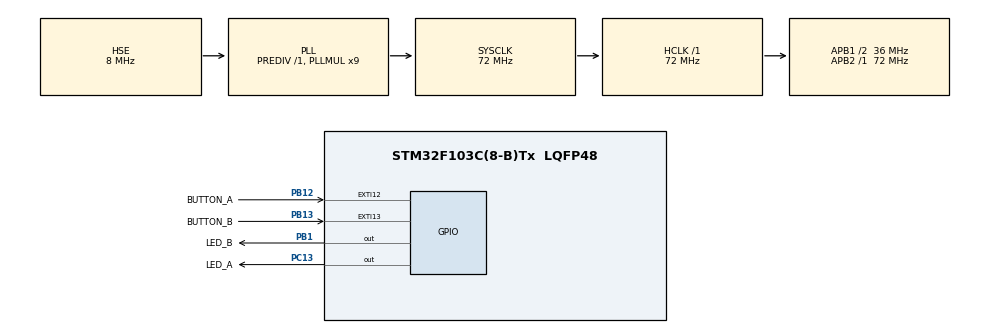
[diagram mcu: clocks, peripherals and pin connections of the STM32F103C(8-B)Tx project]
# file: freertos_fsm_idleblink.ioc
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FREERTOS.Tasks01=defaultTask,24,128,StartDefaultTask,Default,NULL,Dynamic,NULL,NULL
FREERTOS.configUSE_NEWLIB_REENTRANT=1
FREERTOS.configUSE_TICKLESS_IDLE=0
FREERTOS.configUSE_TICK_HOOK=1
Mcu.Family=STM32F1
Mcu.Name=STM32F103C(8-B)Tx
Mcu.Package=LQFP48
NVIC.EXTI15_10_IRQn=true\:5\:0\:false\:false\:true\:true\:true\:true\:true
NVIC.PriorityGroup=NVIC_PRIORITYGROUP_4
NVIC.TIM1_UP_IRQn=true\:15\:0\:true\:false\:true\:false\:false\:true\:true
NVIC.TimeBase=TIM1_UP_IRQn
NVIC.TimeBaseIP=TIM1
PA13.Mode=Serial_Wire
PA13.Signal=SYS_JTMS-SWDIO
PA14.Mode=Serial_Wire
PA14.Signal=SYS_JTCK-SWCLK
PB1.GPIO_Label=LED_B
PB1.PinState=GPIO_PIN_SET
PB1.Signal=GPIO_Output
PB12.GPIO_Label=BUTTON_A
PB12.GPIO_ModeDefaultEXTI=GPIO_MODE_IT_FALLING
PB12.GPIO_PuPd=GPIO_PULLUP
PB12.Signal=GPXTI12
PB13.GPIO_Label=BUTTON_B
PB13.GPIO_ModeDefaultEXTI=GPIO_MODE_IT_FALLING
PB13.GPIO_PuPd=GPIO_PULLUP
PB13.Signal=GPXTI13
PC13-TAMPER-RTC.GPIO_Label=LED_A
PC13-TAMPER-RTC.PinState=GPIO_PIN_SET
PC13-TAMPER-RTC.Signal=GPIO_Output
PC14-OSC32_IN.Mode=LSE-External-Oscillator
PC14-OSC32_IN.Signal=RCC_OSC32_IN
PC15-OSC32_OUT.Mode=LSE-External-Oscillator
PC15-OSC32_OUT.Signal=RCC_OSC32_OUT
PD0-OSC_IN.Mode=HSE-External-Oscillator
PD0-OSC_IN.Signal=RCC_OSC_IN
PD1-OSC_OUT.Mode=HSE-External-Oscillator
PD1-OSC_OUT.Signal=RCC_OSC_OUT
ProjectManager.HeapSize=0x200
ProjectManager.StackSize=0x400
ProjectManager.TargetToolchain=STM32CubeIDE
RCC.AHBFreq_Value=72000000
RCC.APB1CLKDivider=RCC_HCLK_DIV2
RCC.APB1Freq_Value=36000000
RCC.APB1TimFreq_Value=72000000
RCC.APB2Freq_Value=72000000
RCC.APB2TimFreq_Value=72000000
RCC.HCLKFreq_Value=72000000
RCC.PLLMUL=RCC_PLL_MUL9
RCC.PLLSourceVirtual=RCC_PLLSOURCE_HSE
RCC.SYSCLKFreq_VALUE=72000000
RCC.SYSCLKSource=RCC_SYSCLKSOURCE_PLLCLK
RCC.USBFreq_Value=72000000
VP_FREERTOS_VS_CMSIS_V2.Mode=CMSIS_V2
VP_SYS_VS_tim1.Mode=TIM1
board=custom

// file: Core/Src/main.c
/* USER CODE BEGIN Header */
/**
 ******************************************************************************
 * @file           : main.c
 * @brief          : Main program body
 ******************************************************************************
 * @attention
 *
 * <h2><center>&copy; Copyright (c) 2021 STMicroelectronics.
 * All rights reserved.</center></h2>
 *
 * This software component is licensed by ST under BSD 3-Clause license,
 * the "License"; You may not use this file except in compliance with the
 * License. You may obtain a copy of the License at:
 *                        opensource.org/licenses/BSD-3-Clause
 *
 ******************************************************************************
 */
/* USER CODE END Header */
#include "main.h"
#include "cmsis_os.h"

/* USER CODE BEGIN Includes */
#include "fsm_idleblink.h"
#include "user_gpio.h"
/* USER CODE END Includes */

/* Definitions for defaultTask */
osThreadId_t defaultTaskHandle;
const osThreadAttr_t defaultTask_attributes = {
		.name = "defaultTask",
		.stack_size = 128 * 4,
		.priority = (osPriority_t) osPriorityNormal,
};

void SystemClock_Config(void);
static void MX_GPIO_Init(void);
void StartDefaultTask(void *argument);

int main(void)
{

	/* MCU Configuration--------------------------------------------------------*/

	/* Reset of all peripherals, Initializes the Flash interface and the Systick. */
	HAL_Init();

	/* Configure the system clock */
	SystemClock_Config();

	/* Initialize all configured peripherals */
	MX_GPIO_Init();
	/* USER CODE BEGIN 2 */
	user_gpio_init();
	fsm_idleblink_init();
	/* USER CODE END 2 */

	/* Init scheduler */
	osKernelInitialize();

	/* Create the thread(s) */
	/* creation of defaultTask */
	defaultTaskHandle = osThreadNew(StartDefaultTask, NULL, &defaultTask_attributes);

	/* Start scheduler */
	osKernelStart();

	/* We should never get here as control is now taken by the scheduler */
	/* Infinite loop */
	while (1)
	{

	}
}

void SystemClock_Config(void)
{
	RCC_OscInitTypeDef RCC_OscInitStruct = {0};
	RCC_ClkInitTypeDef RCC_ClkInitStruct = {0};

	/** Initializes the RCC Oscillators according to the specified parameters
	 * in the RCC_OscInitTypeDef structure.
	 */
	RCC_OscInitStruct.OscillatorType = RCC_OSCILLATORTYPE_HSE;
	RCC_OscInitStruct.HSEState = RCC_HSE_ON;
	RCC_OscInitStruct.HSEPredivValue = RCC_HSE_PREDIV_DIV1;
	RCC_OscInitStruct.HSIState = RCC_HSI_ON;
	RCC_OscInitStruct.PLL.PLLState = RCC_PLL_ON;
	RCC_OscInitStruct.PLL.PLLSource = RCC_PLLSOURCE_HSE;
	RCC_OscInitStruct.PLL.PLLMUL = RCC_PLL_MUL9;
	if (HAL_RCC_OscConfig(&RCC_OscInitStruct) != HAL_OK)
	{
		Error_Handler();
	}

	/** Initializes the CPU, AHB and APB buses clocks
	 */
	RCC_ClkInitStruct.ClockType = RCC_CLOCKTYPE_HCLK|RCC_CLOCKTYPE_SYSCLK
			|RCC_CLOCKTYPE_PCLK1|RCC_CLOCKTYPE_PCLK2;
	RCC_ClkInitStruct.SYSCLKSource = RCC_SYSCLKSOURCE_PLLCLK;
	RCC_ClkInitStruct.AHBCLKDivider = RCC_SYSCLK_DIV1;
	RCC_ClkInitStruct.APB1CLKDivider = RCC_HCLK_DIV2;
	RCC_ClkInitStruct.APB2CLKDivider = RCC_HCLK_DIV1;

	if (HAL_RCC_ClockConfig(&RCC_ClkInitStruct, FLASH_LATENCY_2) != HAL_OK)
	{
		Error_Handler();
	}
}

static void MX_GPIO_Init(void)
{
	GPIO_InitTypeDef GPIO_InitStruct = {0};

	/* GPIO Ports Clock Enable */
	__HAL_RCC_GPIOC_CLK_ENABLE();
	__HAL_RCC_GPIOD_CLK_ENABLE();
	__HAL_RCC_GPIOB_CLK_ENABLE();
	__HAL_RCC_GPIOA_CLK_ENABLE();

	/*Configure GPIO pin Output Level */
	HAL_GPIO_WritePin(LED_A_GPIO_Port, LED_A_Pin, GPIO_PIN_SET);

	/*Configure GPIO pin Output Level */
	HAL_GPIO_WritePin(LED_B_GPIO_Port, LED_B_Pin, GPIO_PIN_SET);

	/*Configure GPIO pin : LED_A_Pin */
	GPIO_InitStruct.Pin = LED_A_Pin;
	GPIO_InitStruct.Mode = GPIO_MODE_OUTPUT_PP;
	GPIO_InitStruct.Pull = GPIO_NOPULL;
	GPIO_InitStruct.Speed = GPIO_SPEED_FREQ_LOW;
	HAL_GPIO_Init(LED_A_GPIO_Port, &GPIO_InitStruct);

	/*Configure GPIO pin : LED_B_Pin */
	GPIO_InitStruct.Pin = LED_B_Pin;
	GPIO_InitStruct.Mode = GPIO_MODE_OUTPUT_PP;
	GPIO_InitStruct.Pull = GPIO_NOPULL;
	GPIO_InitStruct.Speed = GPIO_SPEED_FREQ_LOW;
	HAL_GPIO_Init(LED_B_GPIO_Port, &GPIO_InitStruct);

	/*Configure GPIO pins : BUTTON_A_Pin BUTTON_B_Pin */
	GPIO_InitStruct.Pin = BUTTON_A_Pin|BUTTON_B_Pin;
	GPIO_InitStruct.Mode = GPIO_MODE_IT_FALLING;
	GPIO_InitStruct.Pull = GPIO_PULLUP;
	HAL_GPIO_Init(GPIOB, &GPIO_InitStruct);

	/* EXTI interrupt init*/
	HAL_NVIC_SetPriority(EXTI15_10_IRQn, 5, 0);
	HAL_NVIC_EnableIRQ(EXTI15_10_IRQn);

}

void StartDefaultTask(void *argument)
{
	/* USER CODE BEGIN 5 */
	/* Infinite loop */
	for(;;)
	{
		osDelay(1000);
	}
	/* USER CODE END 5 */
}

void HAL_TIM_PeriodElapsedCallback(TIM_HandleTypeDef *htim)
{
	if (htim->Instance == TIM1) {
		HAL_IncTick();
	}
}

void Error_Handler(void)
{
	__disable_irq();
	while (1)
	{
	}
}

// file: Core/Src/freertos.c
/* USER CODE BEGIN Header */
/**
 ******************************************************************************
 * File Name          : freertos.c
 * Description        : Code for freertos applications
 ******************************************************************************
 * @attention
 *
 * Copyright (c) 2022 STMicroelectronics.
 * All rights reserved.
 *
 * This software is licensed under terms that can be found in the LICENSE file
 * in the root directory of this software component.
 * If no LICENSE file comes with this software, it is provided AS-IS.
 *
 ******************************************************************************
 */
/* USER CODE END Header */

#include "FreeRTOS.h"
#include "task.h"
#include "main.h"

/* USER CODE BEGIN Includes */
#include "fsm_idleblink.h"
/* USER CODE END Includes */

/* Hook prototypes */
void vApplicationTickHook(void);

/* USER CODE BEGIN 3 */
void vApplicationTickHook( void )
{
	/* This function will be called by each tick interrupt if
	configUSE_TICK_HOOK is set to 1 in FreeRTOSConfig.h. User code can be
	added here, but the tick hook is called from an interrupt context, so
	code must not attempt to block, and only the interrupt safe FreeRTOS API
	functions can be used (those that end in FromISR()). */
	fsm_idleblink_tick();
}
/* USER CODE END 3 */
